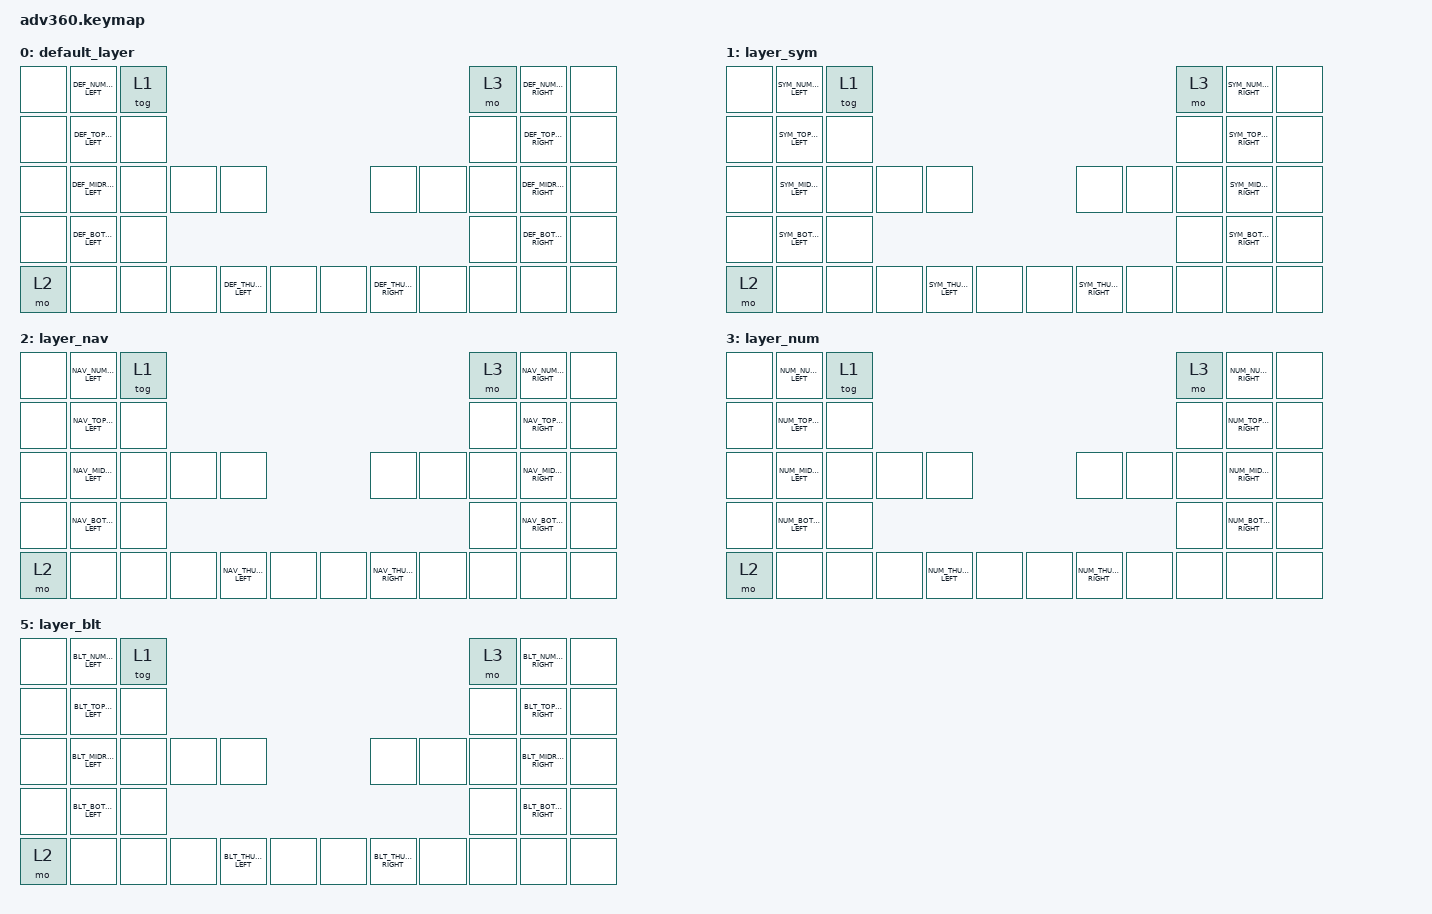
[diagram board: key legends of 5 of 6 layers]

/*
 * Copyright (c) 2020 The ZMK Contributors
 *
 * SPDX-License-Identifier: MIT
 */


/* THIS FILE WAS GENERATED!
 *
 * This file was generated automatically. You may or may not want to
 * edit it directly.
 */

#include "keys.h"                                      // key-position labels
#define KEYS_L LN0 LN1 LN2 LN3 LN4 LN5 \
               LT0 LT1 LT2 LT3 LT4 LT5 \
               LM0 LM1 LM2 LM3 LM4 LM5 \
               LB0 LB1 LB2 LB3 LB4 LB5
#define KEYS_R RN0 RN1 RN2 RN3 RN4 RN5 \
               RT0 RT1 RT2 RT3 RT4 RT5 \
               RM0 RM1 RM2 RM3 RM4 RM5 \
               RB0 RB1 RB2 RB3 RB4 RB5
#define THUMBS_L LHT0 LHT1 LHM0 LHB0 LHB1 LHB2
#define THUMBS_R RHT0 RHT1 RHM0 RHB0 RHB1 RHB2

#define THUMBS THUMBS_L THUMBS_R

#include <behaviors.dtsi>
#include <dt-bindings/zmk/keys.h>
#include <dt-bindings/zmk/bt.h>
#include <dt-bindings/zmk/mouse.h>
#include "../config_common/keymap.h"

/ {
  behaviors {
    #include "macros.dtsi"
    #include "version.dtsi"

    lhm: left_homerow_mods {
        flavor = "balanced";
        tapping-term-ms = <350>;    // <---[[moderate duration]]
        quick-tap-ms = <0>;
        require-prior-idle-ms = <150>;
        compatible = "zmk,behavior-hold-tap";
        #binding-cells = <2>;
        bindings = <&kp>, <&kp>;
        hold-trigger-key-positions = <KEYS_R THUMBS>;
        hold-trigger-on-release;
    };
    rhm: right_homerow_mods {
        flavor = "balanced";
        tapping-term-ms = <350>;    // <---[[moderate duration]]
        quick-tap-ms = <0>;
        require-prior-idle-ms = <150>;
        compatible = "zmk,behavior-hold-tap";
        #binding-cells = <2>;
        bindings = <&kp>, <&kp>;
        hold-trigger-key-positions = <KEYS_L THUMBS>;
        hold-trigger-on-release;
    };
    hm: homerow_mods {
        compatible = "zmk,behavior-hold-tap";
        label = "HOMEROW_MODS";
        #binding-cells = <2>;
        tapping-term-ms = <200>;
        quick_tap_ms = <175>;
        flavor = "balanced";
        bindings = <&kp>, <&kp>;
    };
  };
  combos {
      compatible = "zmk,combos";
      combo_esc {
          timeout-ms = <50>;
          key-positions = <LM3 LM4>;
          bindings = <&kp LC(LBKT)>;
      };
      combo_ae {
          timeout-ms = <50>;
          key-positions = <LT0 LT1>;
          bindings = <&kp RA(Q)>;
      };
      combo_oe {
          timeout-ms = <50>;
          key-positions = <LT1 LT2>;
          bindings = <&kp RA(P)>;
      };
      combo_ue {
          timeout-ms = <50>;
          key-positions = <LT2 LT3>;
          bindings = <&kp RA(Y)>;
      };
      combo_ss {
          timeout-ms = <50>;
          key-positions = <LT3 LT4>;
          bindings = <&kp RA(S)>;
      };
      combo_0 {
          timeout-ms = <50>;
          key-positions = <RB0 RB1>;
          bindings = <&kp N0>;
      };
      combo_1 {
          timeout-ms = <50>;
          key-positions = <RB1 RB2>;
          bindings = <&kp N1>;
      };
      combo_2 {
          timeout-ms = <50>;
          key-positions = <RB2 RB3>;
          bindings = <&kp N2>;
      };
      combo_3 {
          timeout-ms = <50>;
          key-positions = <RB3 RB4>;
          bindings = <&kp N3>;
      };
      combo_4 {
          timeout-ms = <50>;
          key-positions = <RM1 RM2>;
          bindings = <&kp N4>;
      };
      combo_5 {
          timeout-ms = <50>;
          key-positions = <RM2 RM3>;
          bindings = <&kp N5>;
      };
      combo_6 {
          timeout-ms = <50>;
          key-positions = <RM3 RM4>;
          bindings = <&kp N6>;
      };
      combo_7 {
          timeout-ms = <50>;
          key-positions = <RT1 RT2>;
          bindings = <&kp N7>;
      };
      combo_8 {
          timeout-ms = <50>;
          key-positions = <RT2 RT3>;
          bindings = <&kp N8>;
      };
      combo_9 {
          timeout-ms = <50>;
          key-positions = <RT3 RT4>;
          bindings = <&kp N9>;
      };
  };

  keymap {
        compatible = "zmk,keymap";

        default_layer {
            bindings = <
  &none  DEF_NUMROW_LEFT       &tog 1                           &mo 3 DEF_NUMROW_RIGHT       &none
  &none  DEF_TOPROW_LEFT       &none                            &none DEF_TOPROW_RIGHT       &none
  &none  DEF_MIDROW_LEFT       &none &none &none    &none &none &none DEF_MIDROW_RIGHT       &none
  &none  DEF_BOTROW_LEFT                   &none    &none             DEF_BOTROW_RIGHT       &none
  &mo 2  &none &none &none DEF_THUMBS_LEFT &none    &none DEF_THUMBS_RIGHT &none &none &none &none
            >;
        };


        layer_sym {
            bindings = <
  &none  SYM_NUMROW_LEFT       &tog 1                           &mo 3 SYM_NUMROW_RIGHT       &none
  &none  SYM_TOPROW_LEFT       &none                            &none SYM_TOPROW_RIGHT       &none
  &none  SYM_MIDROW_LEFT       &none &none &none    &none &none &none SYM_MIDROW_RIGHT       &none
  &none  SYM_BOTROW_LEFT                   &none    &none             SYM_BOTROW_RIGHT       &none
  &mo 2  &none &none &none SYM_THUMBS_LEFT &none    &none SYM_THUMBS_RIGHT &none &none &none &none
            >;
        };

        layer_nav {
            bindings = <
  &none  NAV_NUMROW_LEFT       &tog 1                           &mo 3 NAV_NUMROW_RIGHT       &none
  &none  NAV_TOPROW_LEFT       &none                            &none NAV_TOPROW_RIGHT       &none
  &none  NAV_MIDROW_LEFT       &none &none &none    &none &none &none NAV_MIDROW_RIGHT       &none
  &none  NAV_BOTROW_LEFT                   &none    &none             NAV_BOTROW_RIGHT       &none
  &mo 2  &none &none &none NAV_THUMBS_LEFT &none    &none NAV_THUMBS_RIGHT &none &none &none &none
            >;
        };
      
        layer_num {
            bindings = <
  &none  NUM_NUMROW_LEFT       &tog 1                           &mo 3 NUM_NUMROW_RIGHT       &none
  &none  NUM_TOPROW_LEFT       &none                            &none NUM_TOPROW_RIGHT       &none
  &none  NUM_MIDROW_LEFT       &none &none &none    &none &none &none NUM_MIDROW_RIGHT       &none
  &none  NUM_BOTROW_LEFT                   &none    &none             NUM_BOTROW_RIGHT       &none
  &mo 2  &none &none &none NUM_THUMBS_LEFT &none    &none NUM_THUMBS_RIGHT &none &none &none &none
            >;
        };

        layer_mse {
            bindings = <
  &none  MSE_NUMROW_LEFT        &tog 1                           &mo 3 MSE_NUMROW_RIGHT        &none
  &none &none &none &none &none &none                            &none &none &none &none &none &none
  &none &none &none &none &none &none &none &none    &none &none &none &none &none &none &none &none
  &none &none &none &none &none &none       &none    &none       &none &none &none &none &none &none
  &mo 2 &none &none &none &none &none &none &none    &none &none &none &none &none &none &none &none
            >;
        };

        layer_blt {
            bindings = <
  &none  BLT_NUMROW_LEFT       &tog 1                           &mo 3 BLT_NUMROW_RIGHT       &none
  &none  BLT_TOPROW_LEFT       &none                            &none BLT_TOPROW_RIGHT       &none
  &none  BLT_MIDROW_LEFT       &none &none &none    &none &none &none BLT_MIDROW_RIGHT       &none
  &none  BLT_BOTROW_LEFT                   &none    &none             BLT_BOTROW_RIGHT       &none
  &mo 2  &none &none &none BLT_THUMBS_LEFT &none    &none BLT_THUMBS_RIGHT &none &none &none &none
            >;
        };
    };
};
